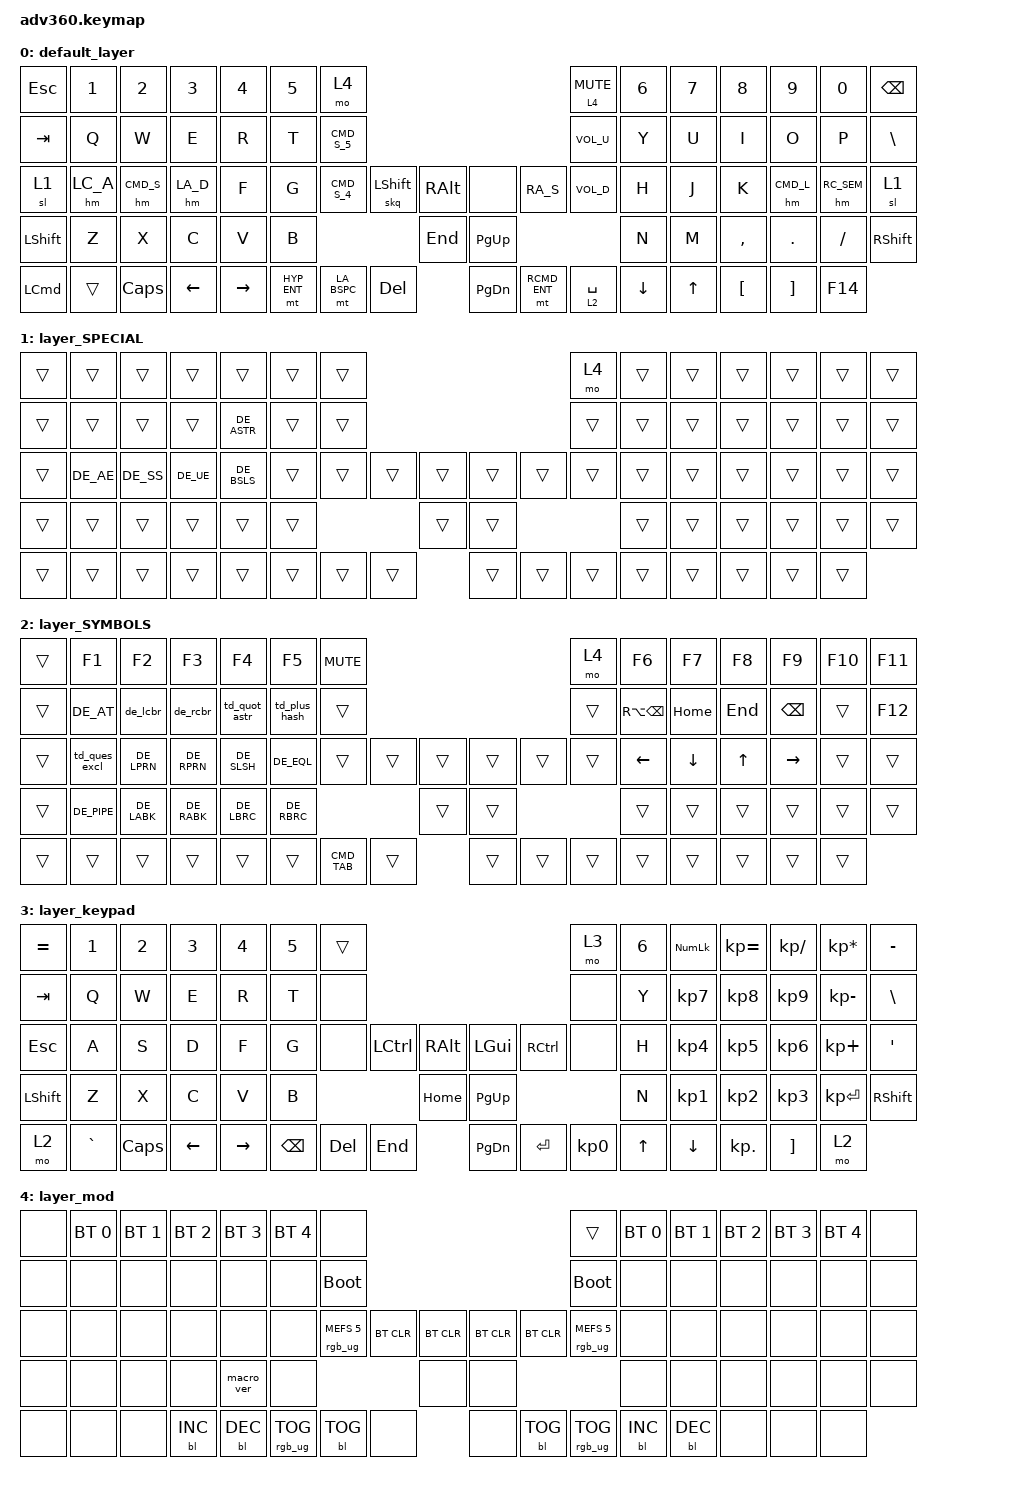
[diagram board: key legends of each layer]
#include <behaviors.dtsi>
#include <dt-bindings/zmk/keys.h>
#include <dt-bindings/zmk/bt.h>
#include <dt-bindings/zmk/rgb.h>
#include <dt-bindings/zmk/backlight.h>

/* MACROS */
#define HYPER LS(RA(LC(LCMD))) 
#define HYP_ENT HYPER ENTER
#define HYP_BSPC HYPER BSPC
#define RA_S RA(SPACE)
#define RA_K RALT K
#define LA_BSPC LALT BSPC
#define LCMD_ENT LCMD ENTER 
#define RCMD_ENT RCMD ENTER 
#define CMD_L RCMD L 
#define CMD_S LCMD S 
#define LA_D LALT D 
#define LC_SEM LCTRL SEMICOLON
#define RC_SEM RCTRL SEMICOLON
#define LC_A LCTRL A
// #define CMD_S LG(S) S
#define CMD_X LG(X) X
#define CMD_C LG(C) C
#define CMD_V LG(V) V
#define CMD_W LG(W) W
#define CMD_T LG(T) T
#define CMD_TAB LG(TAB)

/* german keymap */
#define DE_SS     MINUS       // ß
#define DE_OE     SEMICOLON   // Ö
#define DE_AE     SQT         // Ä
#define DE_UE     LBKT        // Ü
#define DE_SLSH   LS(N7)      // / 
#define DE_BSLS   RA(DE_SS)   // \

#define DE_LPRN LS(N8)        // (
#define DE_RPRN LS(N9)        // )
#define DE_EQL  LS(N0)        // =

#define DE_QUES LS(DE_SS)     // ?
#define DE_EXCL LS(N1)        // !
#define DE_PLUS RBKT          // +
#define DE_ASTR LS(DE_PLUS)   // *
#define DE_HASH NUHS          // #
#define DE_QUOT LS(DE_HASH)   // '
#define DE_AT   RA(Q)         // @

#define DE_LCBR RA(N7)      // {
//#define DE_LCBR LA(N7)      // {
//#define DE_LCBR RALT(N7)      // {
#define DE_LBRC RA(N8)        // [
#define DE_RBRC RA(N9)        // ]
#define DE_RCBR RA(N0)      // }
//#define DE_RCBR LALT(N0)      // }
#define DE_BSLS RA(DE_SS)     // (backslash)

#define DE_LABK GRAVE         // <
#define DE_RABK LS(DE_LABK)   // >
#define DE_PIPE RA(DE_LABK)   // |

#define VOL_U   C_VOL_UP
#define VOL_D   C_VOL_DN
#define MUTE    C_MUTE

// screenshot macros
#define CMD_S_4 LS(LG(N4))
#define CMD_S_5 LS(LG(N5))

// home row mods
#define V_LSHIFT LSHFT V
#define M_LSHIFT LSHFT M

/ {
    behaviors {
      #include "macros.dtsi"
      #include "version.dtsi"
      #ifndef VERSION_MACRO
      macro_ver: macro_ver {
        compatible = "zmk,behavior-macro";
        label = "macro_version";
        #binding-cells = <0>;
        bindings = <&kp RET>;
      };
      #endif

    // hold tab
    hm: homerow_mods {
        compatible = "zmk,behavior-hold-tap";
        label = "HOMEROW_MODS";
        #binding-cells = <2>;
        flavor = "balanced";
        tapping-term-ms = <680>;
        quick_tap_ms = <175>;
        require-prior-idle-ms = <150>;
        bindings = <&kp>, <&kp>;
    };
    // hm2: homerow_mods2 {
    //     compatible = "zmk,behavior-hold-tap";
    //     label = "HOMEROW_MODS2";
    //     #binding-cells = <2>;
    //     flavor = "balanced";
    //     tapping-term-ms = <600>;
    //     quick_tap_ms = <175>;
    //     require-prior-idle-ms = <150>;
    //     bindings = <&kp>, <&kp>;
    // };
    
    skq: sticky_key_quick_release {
        compatible = "zmk,behavior-sticky-key";
        label = "STICKY_KEY_QUICK_RELEASE";
        #binding-cells = <1>;
        bindings = <&kp>;
        release-after-ms = <1000>;
        quick-release;
        ignore-modifiers;
    };

    // taken from: https://github.com/MoonKraken/Adv360-Pro-ZMK/blob/V2.0/config/adv360.keymap
    bhm: normal_hr_mod {
          compatible = "zmk,behavior-hold-tap";
          label = "HOMEROW_MODS3";
          #binding-cells = <2>;
          tapping-term-ms = <170>;
          flavor = "tap-preferred";
          bindings = <&kp>, <&kp>;
    };
    shm: shift_hr_mod {
        compatible = "zmk,behavior-hold-tap";
        label = "SHIFT_HOMEROW_MODS";
        #binding-cells = <2>;
        tapping-term-ms = <120>;
        flavor = "tap-preferred";
        bindings = <&kp>, <&kp>;
    }; 

    td_ques_excl: tap_dance_question_mark_exclamation_mark {
        compatible = "zmk,behavior-tap-dance";
        #binding-cells = <0>;
        tapping-term-ms = <180>;
        bindings = <&kp DE_QUES>, <&kp DE_EXCL>;
    };
    td_quot_astr: tap_dance_quot_astr {
        compatible = "zmk,behavior-tap-dance";
        #binding-cells = <0>;
        tapping-term-ms = <200>;
        bindings = <&kp DE_QUOT>, <&kp DE_ASTR>;
    };
    td_plus_hash: tap_dance_plus_hash {
        compatible = "zmk,behavior-tap-dance";
        #binding-cells = <0>;
        tapping-term-ms = <200>;
        bindings = <&kp DE_PLUS>, <&kp DE_HASH>;
    };
};

macros {
    // Left Curly Brace {
    de_lcbr: de_lcbr {
        compatible = "zmk,behavior-macro";
        #binding-cells = <0>;
        wait-ms = <50>;
        tap-ms = <50>;
        bindings = <&macro_press &kp RALT>, 
                   <&macro_tap &kp N7>, 
                   <&macro_release &kp RALT>;
    };

    // Right Curly Brace }
    de_rcbr: de_rcbr {
        compatible = "zmk,behavior-macro";
        #binding-cells = <0>;
        wait-ms = <50>;
        tap-ms = <50>;
        bindings = <&macro_press &kp RALT>, 
                   <&macro_tap &kp N0>, 
                   <&macro_release &kp RALT>;
    };
};
    // combos {
        
        //key positions: https://github.com/KinesisCorporation/Adv360-Pro-ZMK/blob/V3.0/assets/key-positions.md
        // compatible = "zmk,combos";
        //combo_lshift {
            //timeout-ms = <50>;
            //key-positions = <29 44>; // left and right pinky on home row
            //bindings = <&skq LSHFT>;
        //};
        //combo_lshift2 {
            //timeout-ms = <50>;
            //key-positions = <31 42>; // left and right middle finger on home row
            //bindings = <&skq LSHFT>;
        //};
    // };

  keymap {
    compatible = "zmk,keymap";

        // Layer: 0
        default_layer   {
            bindings = <
                &kp ESC     &kp N1          &kp N2          &kp N3          &kp N4          &kp N5          &mo 4                                                                                                           &lt 4 MUTE  &kp N6          &kp N7          &kp N8          &kp N9          &kp N0          &kp BACKSPACE
                &kp TAB     &kp Q           &kp W           &kp E           &kp R           &kp T           &kp CMD_S_5                                                                                                     &kp VOL_U   &kp Y           &kp U           &kp I           &kp O           &kp P           &kp BSLH
                &sl 1       &hm LC_A        &hm CMD_S       &hm LA_D        &kp F           &kp G           &kp CMD_S_4                 &skq LSHFT      &kp RALT        &none       &kp RA_S                                &kp VOL_D   &kp H           &kp J           &kp K           &hm CMD_L       &hm RC_SEM      &sl 1
                &kp LSHFT   &kp Z           &kp X           &kp C           &kp V           &kp B                                                       &kp END         &kp PG_UP                                                       &kp N           &kp M           &kp COMMA       &kp DOT         &kp FSLH        &kp RSHFT
                &kp LCMD    &trans          &kp CAPS        &kp LEFT        &kp RIGHT                                  &mt HYP_ENT      &mt LA_BSPC     &kp DEL         &kp PG_DN   &mt RCMD_ENT    &lt 2 SPACE                         &kp DOWN        &kp UP          &kp LBKT        &kp RBKT        &kp F14
            >;
        };

        // Layer: 1
        layer_SPECIAL {
            
            bindings = <
                &trans     &trans          &trans          &trans          &trans          &trans          &trans                                                                                                           &mo 4       &trans          &trans          &trans          &trans          &trans          &trans
                &trans     &trans          &trans          &trans          &kp DE_ASTR     &trans          &trans                                                                                                           &trans      &trans          &trans          &trans          &trans          &trans          &trans
                &trans     &kp DE_AE       &kp DE_SS       &kp DE_UE       &kp DE_BSLS     &trans          &trans                       &trans          &trans          &trans      &trans                                  &trans      &trans          &trans          &trans          &trans          &trans          &trans
                &trans     &trans          &trans          &trans          &trans          &trans                                                       &trans          &trans                                                          &trans          &trans          &trans          &trans          &trans          &trans
                &trans     &trans          &trans          &trans          &trans                                      &trans           &trans          &trans          &trans      &trans          &trans                              &trans          &trans          &trans          &trans          &trans
            >;
        };

        // Layer: 2
        layer_SYMBOLS {
            bindings = <
                &trans     &kp F1          &kp F2          &kp F3          &kp F4          &kp F5          &kp C_MUTE                                                                                                       &mo 4       &kp F6          &kp F7          &kp F8          &kp F9          &kp F10         &kp F11
                &trans     &kp DE_AT       &de_lcbr        &de_rcbr        &td_quot_astr   &td_plus_hash   &trans                                                                                                           &trans      &kp RA(BSPC)    &kp HOME        &kp END         &kp BSPC        &trans          &kp F12
                &trans     &td_ques_excl   &kp DE_LPRN     &kp DE_RPRN     &kp DE_SLSH     &kp DE_EQL      &trans                       &trans          &trans          &trans      &trans                                  &trans      &kp LEFT        &kp DOWN        &kp UP          &kp RIGHT       &trans          &trans
                &trans     &kp DE_PIPE     &kp DE_LABK     &kp DE_RABK     &kp DE_LBRC     &kp DE_RBRC                                                  &trans          &trans                                                          &trans          &trans          &trans          &trans          &trans          &trans
                &trans     &trans          &trans          &trans          &trans                                      &trans           &kp CMD_TAB     &trans          &trans      &trans          &trans                              &trans          &trans          &trans          &trans          &trans
            >;
        };

        // Layer: 3
        layer_keypad {
            bindings = <
                &kp EQUAL  &kp N1          &kp N2          &kp N3          &kp N4          &kp N5          &trans                                                                                                           &mo 3       &kp N6          &kp KP_NUM      &kp KP_EQUAL    &kp KP_DIVIDE   &kp KP_MULTIPLY &kp MINUS
                &kp TAB    &kp Q           &kp W           &kp E           &kp R           &kp T           &none                                                                                                            &none       &kp Y           &kp KP_N7       &kp KP_N8       &kp KP_N9       &kp KP_MINUS    &kp BSLH
                &kp ESC    &kp A           &kp S           &kp D           &kp F           &kp G           &none                        &kp LCTRL       &kp RALT        &kp LGUI    &kp RCTRL                               &none       &kp H           &kp KP_N4       &kp KP_N5       &kp KP_N6       &kp KP_PLUS     &kp SQT
                &kp LSHFT  &kp Z           &kp X           &kp C           &kp V           &kp B                                                        &kp HOME        &kp PG_UP                                                       &kp N           &kp KP_N1       &kp KP_N2       &kp KP_N3       &kp KP_ENTER    &kp RSHFT
                &mo 2      &kp GRAVE       &kp CAPS        &kp LEFT        &kp RIGHT                                   &kp BSPC         &kp DEL         &kp END         &kp PG_DN   &kp ENTER       &kp KP_N0                           &kp UP          &kp DOWN        &kp KP_DOT      &kp RBKT        &mo 2
            >;
        };

        // Layer: 4
        layer_mod {
            bindings = <
                 &none     &bt BT_SEL 0    &bt BT_SEL 1    &bt BT_SEL 2    &bt BT_SEL 3    &bt BT_SEL 4    &none                                                                                                            &trans      &bt BT_SEL 0    &bt BT_SEL 1    &bt BT_SEL 2    &bt BT_SEL 3    &bt BT_SEL 4    &none
                 &none     &none           &none           &none           &none           &none           &bootloader                                                                                                      &bootloader &none           &none           &none           &none           &none           &none
                 &none     &none           &none           &none           &none           &none           &rgb_ug RGB_MEFS_CMD 5       &bt BT_CLR      &bt BT_CLR      &bt BT_CLR  &bt BT_CLR                              &rgb_ug RGB_MEFS_CMD 5      &none &none     &none           &none           &none           &none
                 &none     &none           &none           &none           &macro_ver      &none                                                        &none           &none                                                           &none           &none           &none           &none           &none           &none
                 &none     &none           &none           &bl BL_INC      &bl BL_DEC                                  &rgb_ug RGB_TOG  &bl BL_TOG      &none           &none       &bl BL_TOG      &rgb_ug RGB_TOG                     &bl BL_INC      &bl BL_DEC      &none           &none           &none
            >;
        };
  };
};
